# STM32L063x register map
File version: 1.0
Registers are 32-bit, read-write, reset 0x0 unless marked. A register's access mark holds for its fields unless they carry their own. Offsets are from the block's base; [hi:lo] are bit positions; {n}, {i} and the like mark numbered series.

## PWR — Power control
Base 0x40007000
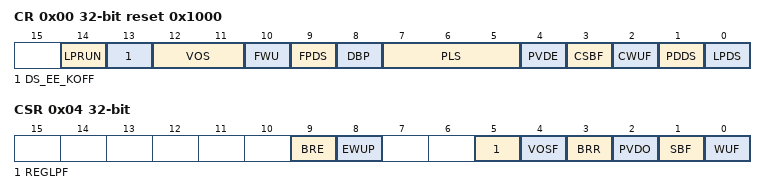
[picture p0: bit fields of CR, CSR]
0x00 CR reset 0x1000 — power control register
  [14] LPRUN — Low power run mode
  [13] DS_EE_KOFF — Deep sleep mode with Flash memory kept off
  [12:11] VOS — Voltage scaling range selection
  [10] FWU — Fast wakeup
  [9] FPDS — Flash power down in Stop mode
  [8] DBP — Disable backup domain write protection
  [7:5] PLS — PVD level selection
  [4] PVDE — Power voltage detector enable
  [3] CSBF — Clear standby flag
  [2] CWUF — Clear wakeup flag
  [1] PDDS — Power down deepsleep
  [0] LPDS — Low-power deep sleep
0x04 CSR access per field — power control/status register
  [9] BRE rw — Backup regulator enable
  [8] EWUP rw — Enable WKUP pin
  [5] REGLPF ro — Regulator LP flag
  [4] VOSF ro — Voltage Scaling select flag
  [3] BRR ro — Backup regulator ready
  [2] PVDO ro — PVD output
  [1] SBF ro — Standby flag
  [0] WUF ro — Wakeup flag

## Flash
Base 0x40022000
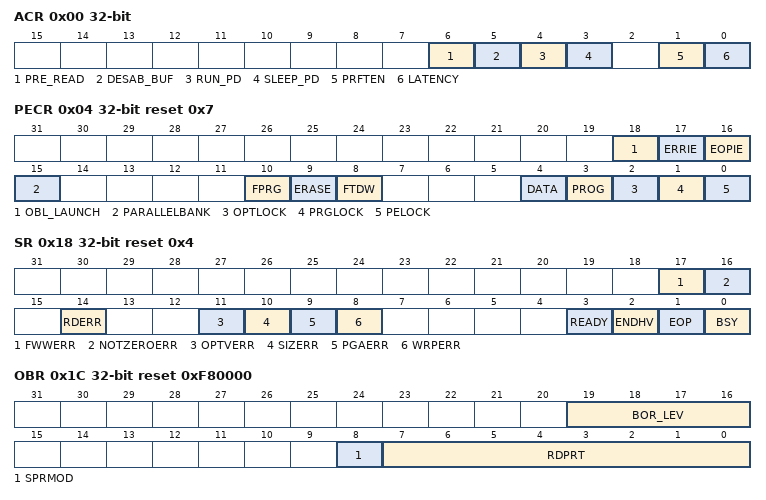
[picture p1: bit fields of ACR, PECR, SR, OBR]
0x00 ACR — Access control register
  [6] PRE_READ — Pre-read data address
  [5] DESAB_BUF — Disable Buffer
  [4] RUN_PD — Flash mode during Run
  [3] SLEEP_PD — Flash mode during Sleep
  [1] PRFTEN — Prefetch enable
  [0] LATENCY
0x04 PECR reset 0x7 — Program/erase control register
  [18] OBL_LAUNCH — Launch the option byte loading
  [17] ERRIE — Error interrupt enable
  [16] EOPIE — End of programming interrupt enable
  [15] PARALLELBANK — Parallel bank mode
  [10] FPRG — Half Page/Double Word programming mode
  [9] ERASE — Page or Double Word erase mode
  [8] FTDW — Fixed time data write for Byte, Half Word and Word programming
  [4] DATA — Data EEPROM selection
  [3] PROG — Program memory selection
  [2] OPTLOCK — Option bytes block lock
  [1] PRGLOCK — Program memory lock
  [0] PELOCK — FLASH_PECR and data EEPROM lock
0x08 PDKEYR wo — Power down key register
  [31:0] PDKEYR — RUN_PD in FLASH_ACR key
0x0C PEKEYR wo — Program/erase key register
  [31:0] PEKEYR — FLASH_PEC and data EEPROM key
0x10 PRGKEYR wo — Program memory key register
  [31:0] PRGKEYR — Program memory key
0x14 OPTKEYR wo — Option byte key register
  [31:0] OPTKEYR — Option byte key
0x18 SR access per field reset 0x4 — Status register
  [17] FWWERR rw
  [16] NOTZEROERR rw
  [14] RDERR rw
  [11] OPTVERR rw — Option validity error
  [10] SIZERR rw — Size error
  [9] PGAERR rw — Programming alignment error
  [8] WRPERR rw — Write protected error
  [3] READY ro — Flash memory module ready after low power mode
  [2] ENDHV ro — End of high voltage
  [1] EOP ro — End of operation
  [0] BSY ro — Write/erase operations in progress
0x1C OBR ro reset 0xF80000 — Option byte register
  [19:16] BOR_LEV
  [8] SPRMOD — Selection of protection mode of WPR bits
  [7:0] RDPRT — Read protection
0x20 WRPR — Write protection register
  [15:0] WRP — Write protection

## EXTI — External interrupt/event controller
Base 0x40010400
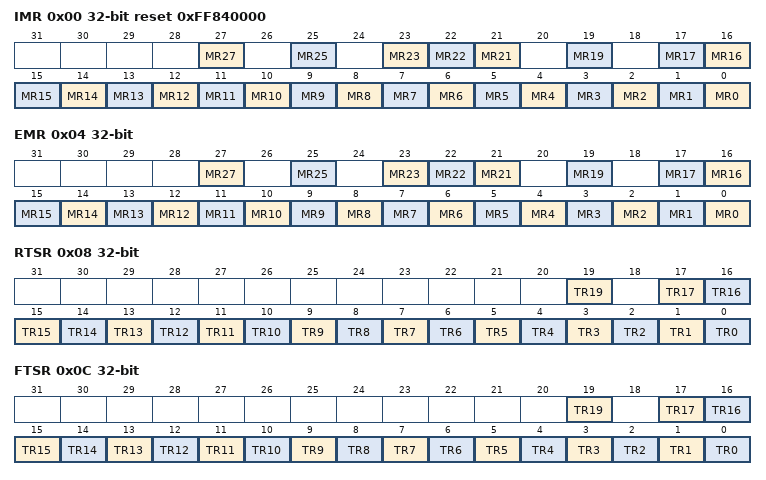
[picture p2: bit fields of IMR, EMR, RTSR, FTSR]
0x00 IMR reset 0xFF840000 — Interrupt mask register (EXTI_IMR)
  [27] MR27 — Interrupt Mask on line 27
  [25] MR25 — Interrupt Mask on line 25
  [23] MR23 — Interrupt Mask on line 23
  [22] MR22 — Interrupt Mask on line 22
  [21] MR21 — Interrupt Mask on line 21
  [19] MR19 — Interrupt Mask on line 19
  [n] MR{n} (n=0..17) — Interrupt Mask on line {n}
0x04 EMR — Event mask register (EXTI_EMR)
  [27] MR27 — Event Mask on line 27
  [25] MR25 — Event Mask on line 25
  [23] MR23 — Event Mask on line 23
  [22] MR22 — Event Mask on line 22
  [21] MR21 — Event Mask on line 21
  [19] MR19 — Event Mask on line 19
  [n] MR{n} (n=0..17) — Event Mask on line {n}
0x08 RTSR — Rising Trigger selection register (EXTI_RTSR)
  [19] TR19 — Rising trigger event configuration of line 19
  [n] TR{n} (n=0..17) — Rising trigger event configuration of line {n}
0x0C FTSR — Falling Trigger selection register (EXTI_FTSR)
  [19] TR19 — Falling trigger event configuration of line 19
  [n] TR{n} (n=0..17) — Falling trigger event configuration of line {n}
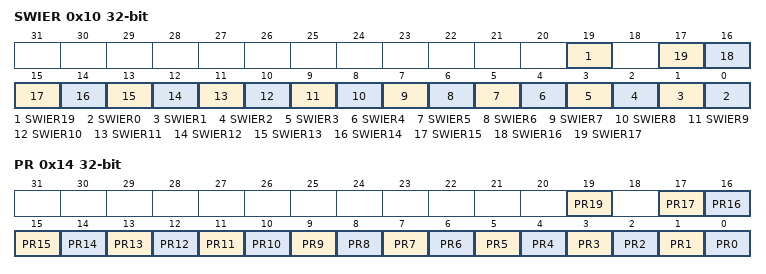
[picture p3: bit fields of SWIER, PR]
0x10 SWIER — Software interrupt event register (EXTI_SWIER)
  [19] SWIER19 — Software Interrupt on line 19
  [n] SWIER{n} (n=0..17) — Software Interrupt on line {n}
0x14 PR — Pending register (EXTI_PR)
  [19] PR19 — Pending bit 19
  [n] PR{n} (n=0..17) — Pending bit {n}
